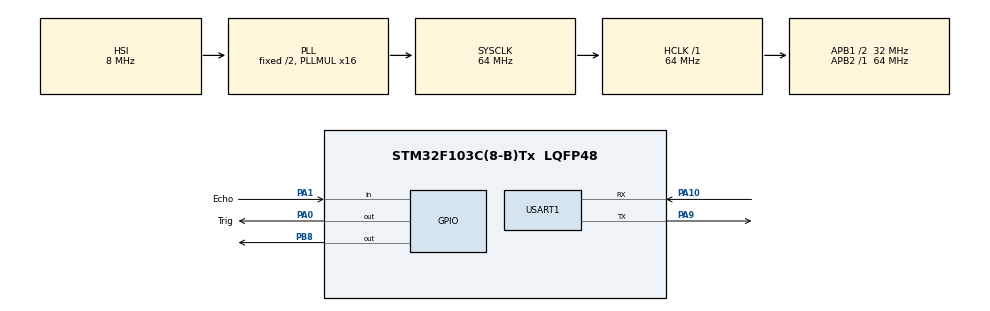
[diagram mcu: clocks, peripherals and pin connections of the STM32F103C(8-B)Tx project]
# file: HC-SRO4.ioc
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Mcu.Family=STM32F1
Mcu.Name=STM32F103C(8-B)Tx
Mcu.Package=LQFP48
NVIC.PriorityGroup=NVIC_PRIORITYGROUP_4
PA0-WKUP.GPIO_Label=Trig
PA0-WKUP.GPIO_Speed=GPIO_SPEED_FREQ_LOW
PA0-WKUP.PinState=GPIO_PIN_SET
PA0-WKUP.Signal=GPIO_Output
PA1.GPIO_Label=Echo
PA1.GPIO_PuPd=GPIO_NOPULL
PA1.Signal=GPIO_Input
PA10.Mode=Asynchronous
PA10.Signal=USART1_RX
PA13.Mode=JTAG_5_pins
PA13.Signal=SYS_JTMS-SWDIO
PA14.Mode=JTAG_5_pins
PA14.Signal=SYS_JTCK-SWCLK
PA15.Mode=JTAG_5_pins
PA15.Signal=SYS_JTDI
PA9.Mode=Asynchronous
PA9.Signal=USART1_TX
PB3.Mode=JTAG_5_pins
PB3.Signal=SYS_JTDO-TRACESWO
PB4.Mode=JTAG_5_pins
PB4.Signal=SYS_NJTRST
PB8.Signal=GPIO_Output
ProjectManager.HeapSize=0x200
ProjectManager.StackSize=0x400
ProjectManager.TargetToolchain=EWARM
RCC.AHBFreq_Value=64000000
RCC.APB1CLKDivider=RCC_HCLK_DIV2
RCC.APB1Freq_Value=32000000
RCC.APB1TimFreq_Value=64000000
RCC.APB2Freq_Value=64000000
RCC.APB2TimFreq_Value=64000000
RCC.HCLKFreq_Value=64000000
RCC.PLLMUL=RCC_PLL_MUL16
RCC.SYSCLKFreq_VALUE=64000000
RCC.SYSCLKSource=RCC_SYSCLKSOURCE_PLLCLK
RCC.USBFreq_Value=64000000
TIM2.Period=65535
TIM2.Prescaler=63
USART1.VirtualMode=VM_ASYNC
VP_TIM2_VS_ClockSourceINT.Mode=Internal
board=HC-SRO4

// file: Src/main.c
/**
  ******************************************************************************
  * File Name          : main.c
  * Description        : Main program body
  ******************************************************************************
  *
  * COPYRIGHT(c) 2017 STMicroelectronics
  *
  * Redistribution and use in source and binary forms, with or without modification,
  * are permitted provided that the following conditions are met:
  *   1. Redistributions of source code must retain the above copyright notice,
  *      this list of conditions and the following disclaimer.
  *   2. Redistributions in binary form must reproduce the above copyright notice,
  *      this list of conditions and the following disclaimer in the documentation
  *      and/or other materials provided with the distribution.
  *   3. Neither the name of STMicroelectronics nor the names of its contributors
  *      may be used to endorse or promote products derived from this software
  *      without specific prior written permission.
  *
  * THIS SOFTWARE IS PROVIDED BY THE COPYRIGHT HOLDERS AND CONTRIBUTORS "AS IS"
  * AND ANY EXPRESS OR IMPLIED WARRANTIES, INCLUDING, BUT NOT LIMITED TO, THE
  * IMPLIED WARRANTIES OF MERCHANTABILITY AND FITNESS FOR A PARTICULAR PURPOSE ARE
  * DISCLAIMED. IN NO EVENT SHALL THE COPYRIGHT HOLDER OR CONTRIBUTORS BE LIABLE
  * FOR ANY DIRECT, INDIRECT, INCIDENTAL, SPECIAL, EXEMPLARY, OR CONSEQUENTIAL
  * DAMAGES (INCLUDING, BUT NOT LIMITED TO, PROCUREMENT OF SUBSTITUTE GOODS OR
  * SERVICES; LOSS OF USE, DATA, OR PROFITS; OR BUSINESS INTERRUPTION) HOWEVER
  * CAUSED AND ON ANY THEORY OF LIABILITY, WHETHER IN CONTRACT, STRICT LIABILITY,
  * OR TORT (INCLUDING NEGLIGENCE OR OTHERWISE) ARISING IN ANY WAY OUT OF THE USE
  * OF THIS SOFTWARE, EVEN IF ADVISED OF THE POSSIBILITY OF SUCH DAMAGE.
  *
  ******************************************************************************
  */
#include "stm32f1xx_hal.h"
#include "tim.h"
#include "usart.h"
#include "gpio.h"

/* USER CODE BEGIN PV */
/* Private variables ---------------------------------------------------------*/

/* USER CODE END PV */

void SystemClock_Config(void);
void Error_Handler(void);

/* USER CODE BEGIN PFP */
/* Private function prototypes -----------------------------------------------*/

/* USER CODE END PFP */

/* USER CODE BEGIN 0 */
int v1=0,v2=0;
float distance=0.0;
/* USER CODE END 0 */

int main(void)
{

  /* MCU Configuration----------------------------------------------------------*/

  /* Reset of all peripherals, Initializes the Flash interface and the Systick. */
  HAL_Init();

  /* Configure the system clock */
  SystemClock_Config();

  /* Initialize all configured peripherals */
  MX_GPIO_Init();
  MX_TIM2_Init();
  MX_USART1_UART_Init();
  SystemClock_Config();

  /* USER CODE BEGIN 2 */
    printf("Hello world!\r\n");
  /* USER CODE END 2 */

  /* Infinite loop */
  while (1)
  {

  /* USER CODE BEGIN 3 */

    /*
        if(HAL_TIM_Base_Start(&htim2)!=HAL_OK)
        {
                printf("Error!\r\n");
        }
        HAL_GPIO_WritePin(Trig_GPIO_Port,Trig_Pin,GPIO_PIN_SET);
        HAL_Delay(1);//20us+高电平触发信号
        HAL_GPIO_WritePin(Trig_GPIO_Port,Trig_Pin,GPIO_PIN_RESET);
        while(!HAL_GPIO_ReadPin(Echo_GPIO_Port, Echo_Pin));//等待回应线变高
        v1=htim2.Instance->CNT;
        while(HAL_GPIO_ReadPin(Echo_GPIO_Port, Echo_Pin));//等待回应线变低
        v2=htim2.Instance->CNT;
        htim2.Instance->CNT=0;//清0计数器
        distance=(v2-v1)*17/(float)1000;
        printf("distance=%0.1f cm!\r\n",distance);

        HAL_Delay(400);

    */
        HAL_GPIO_WritePin(GPIOB, GPIO_PIN_8, GPIO_PIN_RESET);
        HAL_Delay(100);
        HAL_GPIO_WritePin(GPIOB, GPIO_PIN_8, GPIO_PIN_SET);
        HAL_Delay(100);

  }

  /* USER CODE END 3 */

}

/** System Clock Configuration
*/
void SystemClock_Config(void)
{

  RCC_OscInitTypeDef RCC_OscInitStruct;
  RCC_ClkInitTypeDef RCC_ClkInitStruct;

  RCC_OscInitStruct.OscillatorType = RCC_OSCILLATORTYPE_HSI;
  RCC_OscInitStruct.HSIState = RCC_HSI_ON;
  RCC_OscInitStruct.HSICalibrationValue = 16;
  RCC_OscInitStruct.PLL.PLLState = RCC_PLL_ON;
  RCC_OscInitStruct.PLL.PLLSource = RCC_PLLSOURCE_HSI_DIV2;
  RCC_OscInitStruct.PLL.PLLMUL = RCC_PLL_MUL16;
  if (HAL_RCC_OscConfig(&RCC_OscInitStruct) != HAL_OK)
  {
    Error_Handler();
  }

  RCC_ClkInitStruct.ClockType = RCC_CLOCKTYPE_HCLK|RCC_CLOCKTYPE_SYSCLK
                              |RCC_CLOCKTYPE_PCLK1|RCC_CLOCKTYPE_PCLK2;
  RCC_ClkInitStruct.SYSCLKSource = RCC_SYSCLKSOURCE_PLLCLK;
  RCC_ClkInitStruct.AHBCLKDivider = RCC_SYSCLK_DIV1;
  RCC_ClkInitStruct.APB1CLKDivider = RCC_HCLK_DIV2;
  RCC_ClkInitStruct.APB2CLKDivider = RCC_HCLK_DIV1;
  if (HAL_RCC_ClockConfig(&RCC_ClkInitStruct, FLASH_LATENCY_2) != HAL_OK)
  {
    Error_Handler();
  }

  HAL_SYSTICK_Config(HAL_RCC_GetHCLKFreq()/1000);

  HAL_SYSTICK_CLKSourceConfig(SYSTICK_CLKSOURCE_HCLK);

  /* SysTick_IRQn interrupt configuration */
  HAL_NVIC_SetPriority(SysTick_IRQn, 0, 0);
}

void Error_Handler(void)
{
  while(1)
  {
  }
}

/************************ (C) COPYRIGHT STMicroelectronics *****END OF FILE****/
